# D2522AA register map
Vendor: Dialog; Series: D2522AA; File version: 1.2
CPU: CM0 r1p0, little endian, MPU, FPU, 3 interrupt priority bits
Registers are 32-bit, read-write, reset 0x0 unless marked. A register's access mark holds for its fields unless they carry their own. Offsets are from the block's base; [hi:lo] are bit positions; {n}, {i} and the like mark numbered series.

## RFCU — RFCU registers
Base 0x40020000
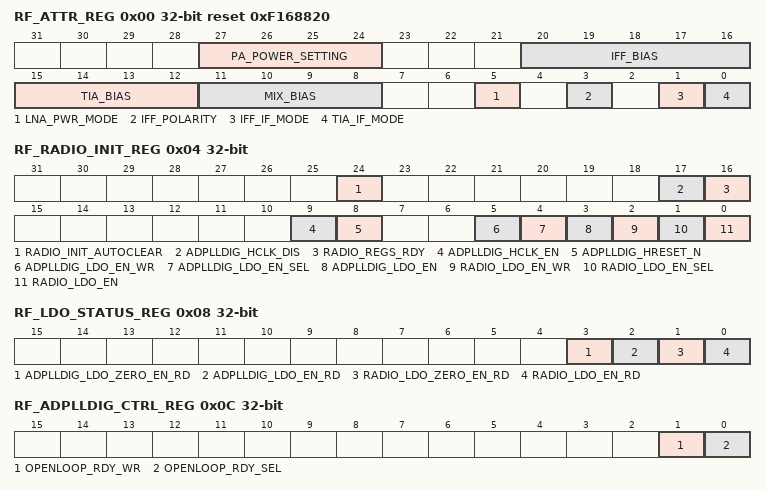
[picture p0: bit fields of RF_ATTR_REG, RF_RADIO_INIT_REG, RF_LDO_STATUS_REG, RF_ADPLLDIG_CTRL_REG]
0x00 RF_ATTR_REG reset 0xF168820 — Radio attributes register
  [27:24] PA_POWER_SETTING — Dynamic setting to control the PA power by enabling units 1 : minimum power 15: maximum power
  [20:16] IFF_BIAS — Tuning of the IFF bias current.
  [15:12] TIA_BIAS — Tuning of the TIA bias current.
  [11:8] MIX_BIAS — Tuning of the Mixer bias current.
  [5] LNA_PWR_MODE — LNA power mode 0: Low power (default) 1: High performance
  [3] IFF_POLARITY
  [1] IFF_IF_MODE — IFF IF mode 0: 1 Mbps (default) 1: 2 Mbps
  [0] TIA_IF_MODE — TIA IF mode 0: 1 Mbps (default) 1: 2 Mbps
0x04 RF_RADIO_INIT_REG — Radio initialization register
  [24] RADIO_INIT_AUTOCLEAR — LDO mode 0: Clear ADPLLDIG_LDO_EN from FW. 1: Auto-clear ADPLLDIG_LDO_EN on radio_busy negedge if there is no package in IFS.
  [17] ADPLLDIG_HCLK_DIS — Disable adplldig hclk. 0: Do nothing 1: Disable (It is auto-cleared when ADPLLDIG_HCLK_EN is set to 1) Remark: Since ADPLLDIG_HCLK_EN has higher priority over ADPLLDIG_HCLK_DIS, ADPLLDIG_HCLK_DIS bit-field cannot be set to 1 with "SetBits()" commands, which access the two bit-fields at the same time. To be able to ADPLLDIG_HCLK_DIS bit-field to 1, "SetByte()" command should be used.
  [16] RADIO_REGS_RDY — ADPLLDIG regs loading status bit (Auto-clear to 0 at phy_busy pos-edge or when ADPLLDIG LDO is off) 0: Loading preferred values is not finished. 1: Loading preferred values is finished.
  [9] ADPLLDIG_HCLK_EN — Enable adplldig hclk. 0: Disable 1: Enable (It is auto-cleared when ADPLLDIG_HCLK_DIS is set to 1)
  [8] ADPLLDIG_HRESET_N — Reset Adplldig register file 0: Reset state. 1: Reset is released.
  [5] ADPLLDIG_LDO_EN_WR — ADPLLDIG LDO EN overrule value.
  [4] ADPLLDIG_LDO_EN_SEL — Select ADPLLDIG_LDO_EN_WR.
  [3] ADPLLDIG_LDO_EN — ADPLLDIG LDO enable bit.
  [2] RADIO_LDO_EN_WR — Radio LDO EN overrule value.
  [1] RADIO_LDO_EN_SEL — Select RADIO_LDO_EN_WR.
  [0] RADIO_LDO_EN — Radio LDO enable bit.
0x08 RF_LDO_STATUS_REG — Read out value of LDO enables
  [3] ADPLLDIG_LDO_ZERO_EN_RD ro — ADPLLDIG LDO zero enable bit.
  [2] ADPLLDIG_LDO_EN_RD ro — ADPLLDIG LDO enable bit.
  [1] RADIO_LDO_ZERO_EN_RD ro — Radio LDO zero enable bit.
  [0] RADIO_LDO_EN_RD ro — Radio LDO enable bit.
0x0C RF_ADPLLDIG_CTRL_REG — Adplldig specific settings register
  [1] OPENLOOP_RDY_WR — Overrule value for the openloop_rdy.
  [0] OPENLOOP_RDY_SEL — Overrule the openloop_rdy from adplldig. 0: Normal function (default) 1: Overrule the openloop_rdy by OPENLOOP_RDY_WR
0x10 RF_AGC_EXT_LUT_REG — AGC_LUT register
  [9:0] AGC_EXT_LUT — LUT for the AGC value, to be selected by dem_agc from the demodulator. Gain settings 10, 11, 12 (so the last 3) use the value of gain setting 9
0x14 RF_CALSTATE_REG — cal_state read-out register
  [3:0] CALSTATE ro — Value of the calstate state machine
0x18 RF_SCAN_FEEDBACK_REG (reset mask 0xFFFF) — scan feedback register
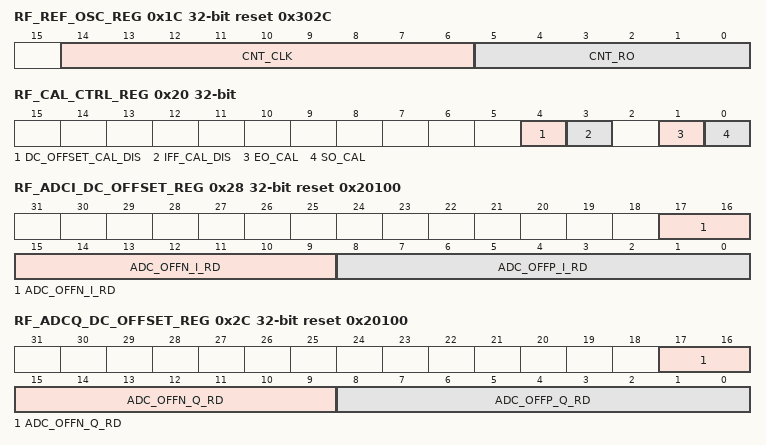
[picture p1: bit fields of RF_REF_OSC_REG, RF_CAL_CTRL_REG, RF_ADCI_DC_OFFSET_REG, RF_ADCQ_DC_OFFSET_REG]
0x1C RF_REF_OSC_REG reset 0x302C
  [14:6] CNT_CLK — number of clock pulses corresponding to the value of CNT_RO
  [5:0] CNT_RO — number of reference oscillator periods that need to be counted
0x20 RF_CAL_CTRL_REG — Calibration FSM control
  [4] DC_OFFSET_CAL_DIS — Do not calibrate the VGA2 Offset during Cal cycle
  [3] IFF_CAL_DIS — Do not calibrate the IFF center frequency during Cal cycle
  [1] EO_CAL ro — End of calibration trigger. Reading returns the eo_cal status signal which can be cleared by writing to RF_IRQ_CTRL_REG.EO_CAL_CLEAR
  [0] SO_CAL — Start of calibration trigger.Writing a 1 starts calibration.1Reading returns the calibration status (1 = busy calibrating).
0x24 RF_IRQ_CTRL_REG reset 0x1 — IRQ clear register
  [0] EO_CAL_CLEAR wo — Writing any value to this bit clears eo_cal interrupt.
0x28 RF_ADCI_DC_OFFSET_REG reset 0x20100 — Must be Retained
  [17:9] ADC_OFFN_I_RD ro — DC offset compensation in the I path (inverting input) in sign-magnitude notarion (i.e. -31 : 1 : 31 mV)
  [8:0] ADC_OFFP_I_RD ro — DC offset compensation in the I path (non-inverting input) in sign-magnitude notarion (i.e. -31 : 1 : 31 mV)
0x2C RF_ADCQ_DC_OFFSET_REG reset 0x20100 — Must be Retained
  [17:9] ADC_OFFN_Q_RD ro — DC offset compensation in the Q path (inverting input) in sign-magnitude notarion (i.e. -31 : 1 : 31 mV)
  [8:0] ADC_OFFP_Q_RD ro — DC offset compensation in the Q path (non-inverting input) in sign-magnitude notarion (i.e. -31 : 1 : 31 mV)
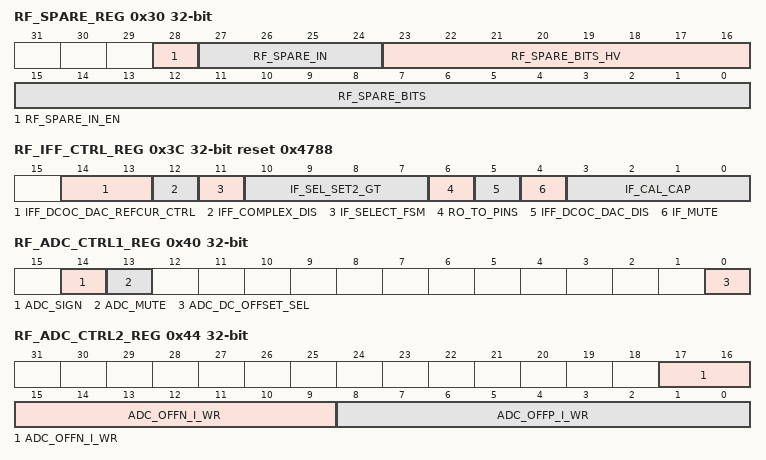
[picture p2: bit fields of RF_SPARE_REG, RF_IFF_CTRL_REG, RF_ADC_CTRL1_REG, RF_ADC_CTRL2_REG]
0x30 RF_SPARE_REG — Spare register for radio
  [28] RF_SPARE_IN_EN — Enable reading of the spare inputs from radio.
  [27:24] RF_SPARE_IN ro — Spare inputs from radio.
  [23:16] RF_SPARE_BITS_HV — Spare bits for High voltage.
  [15:0] RF_SPARE_BITS — Spare bits.
0x3C RF_IFF_CTRL_REG reset 0x4788 — IFF control register
  [14:13] IFF_DCOC_DAC_REFCUR_CTRL
  [12] IFF_COMPLEX_DIS — Put IF-filter in lowpass configuration
  [11] IF_SELECT_FSM — '0': use one of the IFF_CC_1M/2M_SET1/2, depending on IFF_IF_MODE and IF_SELSET_GT '1': use the value from the calibration FSM
  [10:7] IF_SEL_SET2_GT — Setting to control when IF_CAL_CAP_1M/2M_SET2 is used. If AGC > IF_SEL_SET2_GT, SET2 is used.Else, SET1 is used.
  [6] RO_TO_PINS — '0': normal operation; '1': Enable reference oscillator.
  [5] IFF_DCOC_DAC_DIS — Disable the DC offset current DAC
  [4] IF_MUTE — '0': normal operation; '1': Mute IFF by short circuit of VGA1 input. Note: set TGATE_MIXER_IF to '0' for isolation from the IRM
  [3:0] IF_CAL_CAP ro — Current value applied to IF_CAL_CAP
0x40 RF_ADC_CTRL1_REG — ADC control register
  [14] ADC_SIGN — Change polarity of ADC input.
  [13] ADC_MUTE — 0: Normal operation 1: Short the inputs of the ADC (used for DC offset cal)
  [0] ADC_DC_OFFSET_SEL — 0: Normal operation (i.e. Use automatically calibrated value) 1: Use ADC_OFFx_y_WR to set the DC offset compensation values in the ADC (x = N or P, y = I or Q
0x44 RF_ADC_CTRL2_REG — ADC control register
  [17:9] ADC_OFFN_I_WR — External value for the DC offset compensation in the I path negative side. With common mode input voltage at Vpwrp/2, this value is 512-ADC_OFFP_Q_WR.
  [8:0] ADC_OFFP_I_WR — External value for the DC offset compensation in the I path positive side.
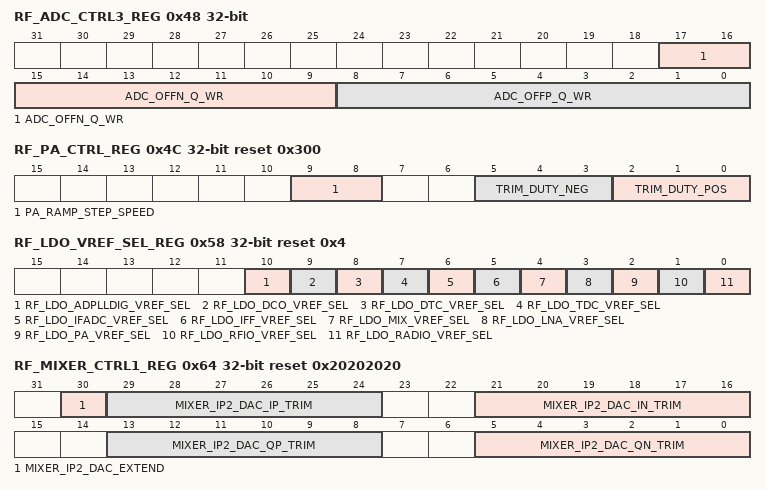
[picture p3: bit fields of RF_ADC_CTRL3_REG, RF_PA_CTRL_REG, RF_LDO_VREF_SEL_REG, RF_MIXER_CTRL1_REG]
0x48 RF_ADC_CTRL3_REG — ADC control register
  [17:9] ADC_OFFN_Q_WR — External value for the DC offset compensation in the Q path negative side. With common mode input voltage at Vpwrp/2, this value is 512-ADC_OFFP_Q_WR.
  [8:0] ADC_OFFP_Q_WR — External value for the DC offset compensation in the Q path positive side.
0x4C RF_PA_CTRL_REG reset 0x300 — PA control register
  [9:8] PA_RAMP_STEP_SPEED — 00 no ramping 01 ramp step 125 ns 10 ramp step 250 ns 11 ramp step 500 ns
  [5:3] TRIM_DUTY_NEG — Trims the duty-cycle (current starving) resistor at the nmos side 0: lowest resistance (shorted, fastest falling edge) 7: max resistance (slowest falling edge)
  [2:0] TRIM_DUTY_POS — Trims the duty-cycle (current starving) resistor at the pmos side 0: lowest resistance (shorted, fastest rising edge) 7: max resistance (slowest rising edge)
0x58 RF_LDO_VREF_SEL_REG reset 0x4 — Vref sel control register
  [10] RF_LDO_ADPLLDIG_VREF_SEL, [9] RF_LDO_DCO_VREF_SEL, [8] RF_LDO_DTC_VREF_SEL, [7] RF_LDO_TDC_VREF_SEL, [6] RF_LDO_IFADC_VREF_SEL, [5] RF_LDO_IFF_VREF_SEL, [4] RF_LDO_MIX_VREF_SEL, [3] RF_LDO_LNA_VREF_SEL, [2] RF_LDO_PA_VREF_SEL, [1] RF_LDO_RFIO_VREF_SEL, [0] RF_LDO_RADIO_VREF_SEL
0x64 RF_MIXER_CTRL1_REG reset 0x20202020 — Mixer control register
  [30] MIXER_IP2_DAC_EXTEND — Controls the slope of the IP2 DACs for the 3 LSBs 0: DAC slope normal 1: DAC slope doubled
  [29:24] MIXER_IP2_DAC_IP_TRIM — Trims the IP DAC. Step = 3.9mV (LSB) for MIXER_IP2_DAC_EXTEND = 0 Step = 2* 3.9mV (LSB) for MIXER_IP2_DAC_EXTEND = 1 0: Lowest voltage 63: Highest voltage
  [21:16] MIXER_IP2_DAC_IN_TRIM — Trims the IN DAC. Step = 3.9mV (LSB) for MIXER_IP2_DAC_EXTEND = 0 Step = 2* 3.9mV (LSB) for MIXER_IP2_DAC_EXTEND = 1 0: Lowest voltage 63: Highest voltage
  [13:8] MIXER_IP2_DAC_QP_TRIM — Trims the QP DAC. Step = 3.9mV (LSB) for MIXER_IP2_DAC_EXTEND = 0 Step = 2* 3.9mV (LSB) for MIXER_IP2_DAC_EXTEND = 1 0: Lowest voltage 63: Highest voltage
  [5:0] MIXER_IP2_DAC_QN_TRIM — Trims the QN DAC. Step = 3.9mV (LSB) for MIXER_IP2_DAC_EXTEND = 0 Step = 2* 3.9mV (LSB) for MIXER_IP2_DAC_EXTEND = 1 0: Lowest voltage 63: Highest voltage
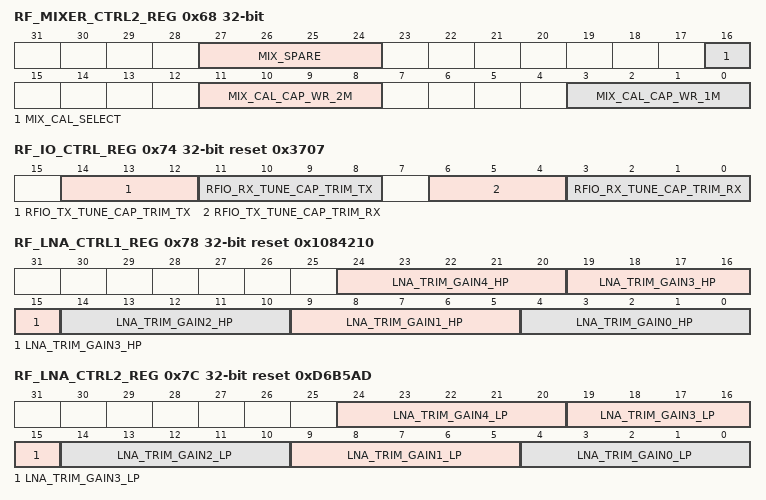
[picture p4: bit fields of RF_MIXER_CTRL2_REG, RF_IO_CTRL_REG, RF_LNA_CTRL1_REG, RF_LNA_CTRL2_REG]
0x68 RF_MIXER_CTRL2_REG — Mixer control register
  [27:24] MIX_SPARE — Spare for the Mixer.
  [16] MIX_CAL_SELECT — 0: use IF_CAL_CAP_1M/2M_SET1, depending on mode. MIX_CAL_CAP_WR is added as offset. 1: use MIX_CAL_CAP_WR directly
  [11:8] MIX_CAL_CAP_WR_2M — External value for calibration of mixer pole capacitance for 2M mode.
  [3:0] MIX_CAL_CAP_WR_1M — External value for calibration of mixer pole capacitance for 1M mode.
0x74 RF_IO_CTRL_REG reset 0x3707 — IO control register
  [14:12] RFIO_TX_TUNE_CAP_TRIM_TX — Trims the TX tuning cap for TX mode. Step = 320fF. 0: Minimum cap (all caps off) 7: Maximum cap (all caps on)
  [11:8] RFIO_RX_TUNE_CAP_TRIM_TX — Trims the RX tuning cap for TX mode. Step = 20fF. 0: Minimum cap (all caps off) 15: Maximum cap (all caps on)
  [6:4] RFIO_TX_TUNE_CAP_TRIM_RX — Trims the TX tuning cap for RX mode. Step = 320fF. 0: Minimum cap (all caps off) 7: Maximum cap (all caps on)
  [3:0] RFIO_RX_TUNE_CAP_TRIM_RX — Trims the RX tuning cap for RX mode. Step = 20fF. 0: Minimum cap (all caps off) 15: Maximum cap (all caps on)
0x78 RF_LNA_CTRL1_REG reset 0x1084210 — LNA control register
  [24:20] LNA_TRIM_GAIN4_HP — High performance LNA gm trim bias settings for CN 00: Lowest gm trim 10: Nominal gm trim 1F: Highest gm trim (Used as gm trim bias value if RF_ATTR_REG[LNA_PWR_MODE] = 1 and lna_gain_sel > 3)
  [5n+4:5n] LNA_TRIM_GAIN{n}_HP (n=0..3) — High performance LNA gm trim bias settings for CN 00: Lowest gm trim 10: Nominal gm trim 1F: Highest gm trim (Used as gm trim bias value if RF_ATTR_REG[LNA_PWR_MODE] = 1 and lna_gain_sel = {n})
0x7C RF_LNA_CTRL2_REG reset 0xD6B5AD — LNA control register
  [24:20] LNA_TRIM_GAIN4_LP — Low power LNA gm trim bias settings for CN 00: Lowest gm trim 10: Nominal gm trim 1F: Highest gm trim (Used as gm trim bias value if RF_ATTR_REG[LNA_PWR_MODE] = 0 and lna_gain_sel > 3)
  [5n+4:5n] LNA_TRIM_GAIN{n}_LP (n=0..3) — Low power LNA gm trim bias settings for CN 00: Lowest gm trim 10: Nominal gm trim 1F: Highest gm trim (Used as gm trim bias value if RF_ATTR_REG[LNA_PWR_MODE] = 0 and lna_gain_sel = {n})
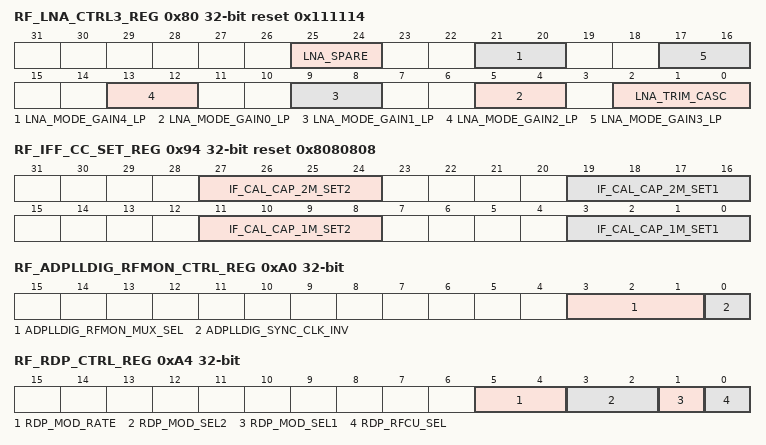
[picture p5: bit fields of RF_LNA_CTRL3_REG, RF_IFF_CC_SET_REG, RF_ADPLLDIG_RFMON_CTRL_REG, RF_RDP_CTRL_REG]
0x80 RF_LNA_CTRL3_REG reset 0x111114 — LNA control register
  [25:24] LNA_SPARE — Spare bits for LNA.
  [21:20] LNA_MODE_GAIN4_LP — Low power LNA mode setting (Used as lna_mode value if RF_ATTR_REG[LNA_PWR_MODE] = 0 and lna_gain_sel > 3)
  [4n+5:4n+4] LNA_MODE_GAIN{n}_LP (n=0..3) — Low power LNA mode setting (Used as lna_mode value if RF_ATTR_REG[LNA_PWR_MODE] = 0 and lna_gain_sel = {n})
  [2:0] LNA_TRIM_CASC — Trims the cascode voltages. 0: lower voltage 7: higher voltage
0x90 RF_IFF_RESULT_REG reset 0x8 — Not retained
  [3:0] IF_CAL_CAP_RD ro — IF calibration result capacitance.
0x94 RF_IFF_CC_SET_REG reset 0x8080808 — Must be retained
  [27:24] IF_CAL_CAP_2M_SET2 — Retained WRITE value. The result of the IF_CAL_CAP calibration should be copied from RF_IFF_RESULT_REG to this register
  [19:16] IF_CAL_CAP_2M_SET1 — Retained WRITE value. The result of the IF_CAL_CAP calibration should be copied from RF_IFF_RESULT_REG to this register
  [11:8] IF_CAL_CAP_1M_SET2 — Retained WRITE value. The result of the IF_CAL_CAP calibration should be copied from RF_IFF_RESULT_REG to this register
  [3:0] IF_CAL_CAP_1M_SET1 — Retained WRITE value. The result of the IF_CAL_CAP calibration should be copied from RF_IFF_RESULT_REG to this register
0x98 RF_IFF_CAL_CAP_STAT_REG reset 0x8 — Current CAL_CAP value applied to the IF
  [3:0] IF_CAL_CAP_RD ro — Reset value is equal to the reset value of RF_IFF_RESULT_REG[IF_CAL_CAP_RD]
0x9C RF_MIX_CAL_CAP_STAT_REG reset 0x8 — Current CAL_CAP value applied to the Mixer
  [3:0] MIX_CAL_CAP_RD ro — The reset value should be equal to the reset value of RF_IFF_CC_SET_REG[RF_IFF_CC_1M_SET1].
0xA0 RF_ADPLLDIG_RFMON_CTRL_REG — Settings for the ADPLLDIG RFMON block
  [3:1] ADPLLDIG_RFMON_MUX_SEL — Mux select for the RFMON data 'b00x: dem_rfmon_data[31:0] 'b010: {dem_rfmon_data[31:16], adplldig_rfmon_data[15:0]} 'b011: {dem_rfmon_data[31:16], adplldig_rfmon_data[31:16]} 'b100: {adplldig_rfmon_data[31:16], dem_rfmon_data[15:0]} 'b101: {adplldig_rfmon_data[15:0], dem_rfmon_data[15:0]} 'b110: adplldig_rfmon_data 'b111: {adplldig_rfmon_data[15:0], adplldig_rfmon_data[31:16]}
  [0] ADPLLDIG_SYNC_CLK_INV — Invert the clock capturing adplldig_rfmon data 0: Do not invert (default) 1: Invert
0xA4 RF_RDP_CTRL_REG — Exposed radio mode control register
  [5:4] RDP_MOD_RATE — 0: The input selected with RDP_MOD_SEL2 is sampled with 32 MHz 1: The input selected with RDP_MOD_SEL2 is sampled with 16 MHz 2: The input selected with RDP_MOD_SEL2 is sampled with 8 MHz 3: Reserved
  [3:2] RDP_MOD_SEL2 — 0: Normal mode - Do not use the RDP_DATA_IN[31:0] signals 1: Exposed radio mode - Use the RDP_DATA[15:0] as modulated input 2: Exposed radio mode - Use the RDP_DATA[31:16] as modulated input 3: Reserved
  [1] RDP_MOD_SEL1 — Provide TX data via GPIOs for exposed radio mode 0: Normal operation - TX data from CMAC 1: Exposed radio mode - TX data from RDP_TX_DATA and RDP_TX_DATA_VALID
  [0] RDP_RFCU_SEL — Provide rx_en/tx_en via GPIOs for exposed radio mode 0: Normal operation - tx_en/rx_en from CMAC 1: Exposed radio mode - tx_en/rx_en from RDP_RX_EN and RDP_TX_EN
0xA8 RF_RFCU_CTRL_REG reset 0x1 — RFCU control register
  [0] RF_RFCU_CLK_DIV — Divide the RFCU clock by 2. 0: 16 MHz 1: 8 MHz (default)
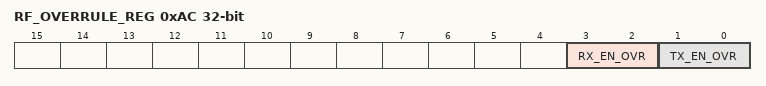
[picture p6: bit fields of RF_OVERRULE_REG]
0xAC RF_OVERRULE_REG — Overrule register
  [3:2] RX_EN_OVR — Overrule RX_EN 'b01: disabled. 'b1x: enabled. 'b00: normal function
  [1:0] TX_EN_OVR — Overrule TX_EN 'b01: disabled. 'b1x: enabled. 'b00: normal function
